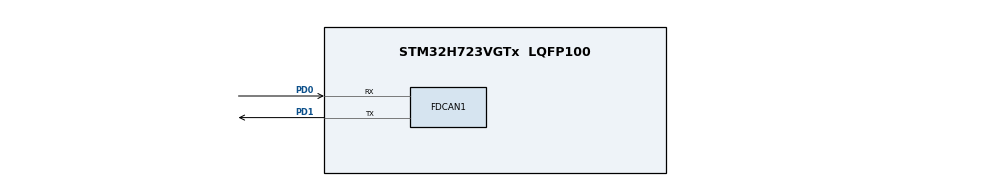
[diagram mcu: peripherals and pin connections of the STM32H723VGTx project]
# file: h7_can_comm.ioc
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CORTEX_M7.default_mode_Activation=1
FDCAN1.CalculateBaudRateNominal=1000000
FDCAN1.CalculateTimeBitNominal=1000
FDCAN1.CalculateTimeQuantumNominal=62.5
FDCAN1.DataPrescaler=6
FDCAN1.DataSyncJumpWidth=2
FDCAN1.DataTimeSeg1=12
FDCAN1.DataTimeSeg2=3
FDCAN1.FrameFormat=FDCAN_FRAME_CLASSIC
FDCAN1.NominalPrescaler=6
FDCAN1.NominalSyncJumpWidth=2
FDCAN1.NominalTimeSeg1=12
FDCAN1.NominalTimeSeg2=3
FDCAN1.ProtocolException=ENABLE
FDCAN1.RxFifo0ElmtsNbr=4
FDCAN1.StdFiltersNbr=1
FDCAN1.TxFifoQueueElmtsNbr=4
FREERTOS.Tasks01=defaultTask,24,128,StartDefaultTask,Default,NULL,Dynamic,NULL,NULL;CANCommTaskFun,24,512,can_comm_task_fun,As weak,NULL,Dynamic,NULL,NULL
Mcu.Family=STM32H7
Mcu.Name=STM32H723VGTx
Mcu.Package=LQFP100
NVIC.FDCAN1_IT0_IRQn=true\:5\:0\:false\:false\:true\:true\:true\:true\:true
NVIC.PriorityGroup=NVIC_PRIORITYGROUP_4
NVIC.TIM4_IRQn=true\:15\:0\:false\:false\:true\:false\:false\:true\:true
NVIC.TimeBase=TIM4_IRQn
NVIC.TimeBaseIP=TIM4
PA13(JTMS/SWDIO).Mode=Serial_Wire
PA13(JTMS/SWDIO).Signal=DEBUG_JTMS-SWDIO
PA14(JTCK/SWCLK).Mode=Serial_Wire
PA14(JTCK/SWCLK).Signal=DEBUG_JTCK-SWCLK
PD0.Mode=FDCAN_Activate
PD0.Signal=FDCAN1_RX
PD1.Mode=FDCAN_Activate
PD1.Signal=FDCAN1_TX
PH0-OSC_IN.Mode=HSE-External-Oscillator
PH0-OSC_IN.Signal=RCC_OSC_IN
PH1-OSC_OUT.Mode=HSE-External-Oscillator
PH1-OSC_OUT.Signal=RCC_OSC_OUT
ProjectManager.HeapSize=0x2000
ProjectManager.StackSize=0x4000
ProjectManager.TargetToolchain=CMake
RCC.ADCFreq_Value=96000000
RCC.APB1Freq_Value=120000000
RCC.APB2Freq_Value=120000000
RCC.APB3Freq_Value=120000000
RCC.APB4Freq_Value=120000000
RCC.CortexFreq_Value=480000000
RCC.D1PPRE=RCC_APB3_DIV2
RCC.D2PPRE1=RCC_APB1_DIV2
RCC.D2PPRE2=RCC_APB2_DIV2
RCC.D3PPRE=RCC_APB4_DIV2
RCC.DIVM1=2
RCC.DIVM2=2
RCC.DIVN1=40
RCC.DIVN2=16
RCC.DIVP1=1
RCC.FDCANCLockSelection=RCC_FDCANCLKSOURCE_PLL2
RCC.HCLKFreq_Value=240000000
RCC.HPRE=RCC_HCLK_DIV2
RCC.HSE_VALUE=24000000
RCC.PLLFRACN=0
RCC.PLLSourceVirtual=RCC_PLLSOURCE_HSE
RCC.SYSCLKFreq_VALUE=480000000
RCC.SYSCLKSource=RCC_SYSCLKSOURCE_PLLCLK
RCC.USBFreq_Value=240000000
VP_FREERTOS_VS_CMSIS_V2.Mode=CMSIS_V2
VP_MEMORYMAP_VS_MEMORYMAP.Mode=CurAppReg
VP_SYS_VS_tim4.Mode=TIM4
board=custom

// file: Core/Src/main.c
/* USER CODE BEGIN Header */
/**
  ******************************************************************************
  * @file           : main.c
  * @brief          : Main program body
  ******************************************************************************
  * @attention
  *
  * Copyright (c) 2026 STMicroelectronics.
  * All rights reserved.
  *
  * This software is licensed under terms that can be found in the LICENSE file
  * in the root directory of this software component.
  * If no LICENSE file comes with this software, it is provided AS-IS.
  *
  ******************************************************************************
  */
/* USER CODE END Header */
#include "main.h"
#include "cmsis_os.h"

FDCAN_HandleTypeDef hfdcan1;

/* Definitions for defaultTask */
osThreadId_t defaultTaskHandle;
const osThreadAttr_t defaultTask_attributes = {
  .name = "defaultTask",
  .stack_size = 128 * 4,
  .priority = (osPriority_t) osPriorityNormal,
};
/* Definitions for CANCommTaskFun */
osThreadId_t CANCommTaskFunHandle;
const osThreadAttr_t CANCommTaskFun_attributes = {
  .name = "CANCommTaskFun",
  .stack_size = 512 * 4,
  .priority = (osPriority_t) osPriorityNormal,
};
/* USER CODE BEGIN PV */
uint8_t recv_buf[8];
/* USER CODE END PV */

void SystemClock_Config(void);
static void MPU_Config(void);
static void MX_GPIO_Init(void);
static void MX_FDCAN1_Init(void);
void StartDefaultTask(void *argument);
void can_comm_task_fun(void *argument);

int main(void)
{

  /* MPU Configuration--------------------------------------------------------*/
  MPU_Config();

  /* MCU Configuration--------------------------------------------------------*/

  /* Reset of all peripherals, Initializes the Flash interface and the Systick. */
  HAL_Init();

  /* Configure the system clock */
  SystemClock_Config();

  /* Initialize all configured peripherals */
  MX_GPIO_Init();
  MX_FDCAN1_Init();

  /* Init scheduler */
  osKernelInitialize();

  /* Create the thread(s) */
  /* creation of defaultTask */
  defaultTaskHandle = osThreadNew(StartDefaultTask, NULL, &defaultTask_attributes);

  /* creation of CANCommTaskFun */
  CANCommTaskFunHandle = osThreadNew(can_comm_task_fun, NULL, &CANCommTaskFun_attributes);

  /* Start scheduler */
  osKernelStart();

  /* We should never get here as control is now taken by the scheduler */

  /* Infinite loop */
  while (1)
  {

  }
}

void SystemClock_Config(void)
{
  RCC_OscInitTypeDef RCC_OscInitStruct = {0};
  RCC_ClkInitTypeDef RCC_ClkInitStruct = {0};

  /** Supply configuration update enable
  */
  HAL_PWREx_ConfigSupply(PWR_LDO_SUPPLY);

  /** Configure the main internal regulator output voltage
  */
  __HAL_PWR_VOLTAGESCALING_CONFIG(PWR_REGULATOR_VOLTAGE_SCALE0);

  while(!__HAL_PWR_GET_FLAG(PWR_FLAG_VOSRDY)) {}

  /** Initializes the RCC Oscillators according to the specified parameters
  * in the RCC_OscInitTypeDef structure.
  */
  RCC_OscInitStruct.OscillatorType = RCC_OSCILLATORTYPE_HSE;
  RCC_OscInitStruct.HSEState = RCC_HSE_ON;
  RCC_OscInitStruct.PLL.PLLState = RCC_PLL_ON;
  RCC_OscInitStruct.PLL.PLLSource = RCC_PLLSOURCE_HSE;
  RCC_OscInitStruct.PLL.PLLM = 2;
  RCC_OscInitStruct.PLL.PLLN = 40;
  RCC_OscInitStruct.PLL.PLLP = 1;
  RCC_OscInitStruct.PLL.PLLQ = 2;
  RCC_OscInitStruct.PLL.PLLR = 2;
  RCC_OscInitStruct.PLL.PLLRGE = RCC_PLL1VCIRANGE_3;
  RCC_OscInitStruct.PLL.PLLVCOSEL = RCC_PLL1VCOWIDE;
  RCC_OscInitStruct.PLL.PLLFRACN = 0;
  if (HAL_RCC_OscConfig(&RCC_OscInitStruct) != HAL_OK)
  {
    Error_Handler();
  }

  /** Initializes the CPU, AHB and APB buses clocks
  */
  RCC_ClkInitStruct.ClockType = RCC_CLOCKTYPE_HCLK|RCC_CLOCKTYPE_SYSCLK
                              |RCC_CLOCKTYPE_PCLK1|RCC_CLOCKTYPE_PCLK2
                              |RCC_CLOCKTYPE_D3PCLK1|RCC_CLOCKTYPE_D1PCLK1;
  RCC_ClkInitStruct.SYSCLKSource = RCC_SYSCLKSOURCE_PLLCLK;
  RCC_ClkInitStruct.SYSCLKDivider = RCC_SYSCLK_DIV1;
  RCC_ClkInitStruct.AHBCLKDivider = RCC_HCLK_DIV2;
  RCC_ClkInitStruct.APB3CLKDivider = RCC_APB3_DIV2;
  RCC_ClkInitStruct.APB1CLKDivider = RCC_APB1_DIV2;
  RCC_ClkInitStruct.APB2CLKDivider = RCC_APB2_DIV2;
  RCC_ClkInitStruct.APB4CLKDivider = RCC_APB4_DIV2;

  if (HAL_RCC_ClockConfig(&RCC_ClkInitStruct, FLASH_LATENCY_3) != HAL_OK)
  {
    Error_Handler();
  }
}

static void MX_FDCAN1_Init(void)
{

  hfdcan1.Instance = FDCAN1;
  hfdcan1.Init.FrameFormat = FDCAN_FRAME_CLASSIC;
  hfdcan1.Init.Mode = FDCAN_MODE_NORMAL;
  hfdcan1.Init.AutoRetransmission = DISABLE;
  hfdcan1.Init.TransmitPause = DISABLE;
  hfdcan1.Init.ProtocolException = ENABLE;
  hfdcan1.Init.NominalPrescaler = 6;
  hfdcan1.Init.NominalSyncJumpWidth = 2;
  hfdcan1.Init.NominalTimeSeg1 = 12;
  hfdcan1.Init.NominalTimeSeg2 = 3;
  hfdcan1.Init.DataPrescaler = 6;
  hfdcan1.Init.DataSyncJumpWidth = 2;
  hfdcan1.Init.DataTimeSeg1 = 12;
  hfdcan1.Init.DataTimeSeg2 = 3;
  hfdcan1.Init.MessageRAMOffset = 0;
  hfdcan1.Init.StdFiltersNbr = 1;
  hfdcan1.Init.ExtFiltersNbr = 0;
  hfdcan1.Init.RxFifo0ElmtsNbr = 4;
  hfdcan1.Init.RxFifo0ElmtSize = FDCAN_DATA_BYTES_8;
  hfdcan1.Init.RxFifo1ElmtsNbr = 0;
  hfdcan1.Init.RxFifo1ElmtSize = FDCAN_DATA_BYTES_8;
  hfdcan1.Init.RxBuffersNbr = 0;
  hfdcan1.Init.RxBufferSize = FDCAN_DATA_BYTES_8;
  hfdcan1.Init.TxEventsNbr = 0;
  hfdcan1.Init.TxBuffersNbr = 0;
  hfdcan1.Init.TxFifoQueueElmtsNbr = 4;
  hfdcan1.Init.TxFifoQueueMode = FDCAN_TX_FIFO_OPERATION;
  hfdcan1.Init.TxElmtSize = FDCAN_DATA_BYTES_8;
  if (HAL_FDCAN_Init(&hfdcan1) != HAL_OK)
  {
    Error_Handler();
  }
  /* USER CODE BEGIN FDCAN1_Init 2 */
  // * FDCAN filter setup
  FDCAN_FilterTypeDef sFilterConfig;
  sFilterConfig.IdType = FDCAN_STANDARD_ID;
  sFilterConfig.FilterIndex = 0;
  sFilterConfig.FilterType = FDCAN_FILTER_MASK;
  sFilterConfig.FilterConfig = FDCAN_FILTER_TO_RXFIFO0;
  sFilterConfig.FilterID1 = 0x0;
  sFilterConfig.FilterID2 = 0x0;
  if (HAL_FDCAN_ConfigFilter(&hfdcan1, &sFilterConfig) != HAL_OK)
  {
    Error_Handler();
  }
  HAL_FDCAN_ConfigGlobalFilter(
    &hfdcan1,
    FDCAN_REJECT,
    FDCAN_REJECT,
    FDCAN_FILTER_REMOTE,
    FDCAN_FILTER_REMOTE
  );
  if (HAL_FDCAN_ActivateNotification(&hfdcan1, FDCAN_IT_RX_FIFO0_NEW_MESSAGE, 0) != HAL_OK)
  {
    Error_Handler();
  }
  if (HAL_FDCAN_Start(&hfdcan1)) {
    Error_Handler();
  }
  /* USER CODE END FDCAN1_Init 2 */

}

static void MX_GPIO_Init(void)
{

  /* GPIO Ports Clock Enable */
  __HAL_RCC_GPIOH_CLK_ENABLE();
  __HAL_RCC_GPIOA_CLK_ENABLE();
  __HAL_RCC_GPIOD_CLK_ENABLE();

}

void StartDefaultTask(void *argument)
{
  for(;;)
  {
    osDelay(1);
  }
}

__weak void can_comm_task_fun(void *argument)
{
  for(;;)
  {
    osDelay(1);
  }
}

 /* MPU Configuration */

void MPU_Config(void)
{
  MPU_Region_InitTypeDef MPU_InitStruct = {0};

  /* Disables the MPU */
  HAL_MPU_Disable();

  /** Initializes and configures the Region and the memory to be protected
  */
  MPU_InitStruct.Enable = MPU_REGION_ENABLE;
  MPU_InitStruct.Number = MPU_REGION_NUMBER0;
  MPU_InitStruct.BaseAddress = 0x0;
  MPU_InitStruct.Size = MPU_REGION_SIZE_4GB;
  MPU_InitStruct.SubRegionDisable = 0x87;
  MPU_InitStruct.TypeExtField = MPU_TEX_LEVEL0;
  MPU_InitStruct.AccessPermission = MPU_REGION_NO_ACCESS;
  MPU_InitStruct.DisableExec = MPU_INSTRUCTION_ACCESS_DISABLE;
  MPU_InitStruct.IsShareable = MPU_ACCESS_SHAREABLE;
  MPU_InitStruct.IsCacheable = MPU_ACCESS_NOT_CACHEABLE;
  MPU_InitStruct.IsBufferable = MPU_ACCESS_NOT_BUFFERABLE;

  HAL_MPU_ConfigRegion(&MPU_InitStruct);
  /* Enables the MPU */
  HAL_MPU_Enable(MPU_PRIVILEGED_DEFAULT);

}

void HAL_TIM_PeriodElapsedCallback(TIM_HandleTypeDef *htim)
{
  if (htim->Instance == TIM4)
  {
    HAL_IncTick();
  }
}

void Error_Handler(void)
{
  __disable_irq();
  while (1)
  {
  }
}
